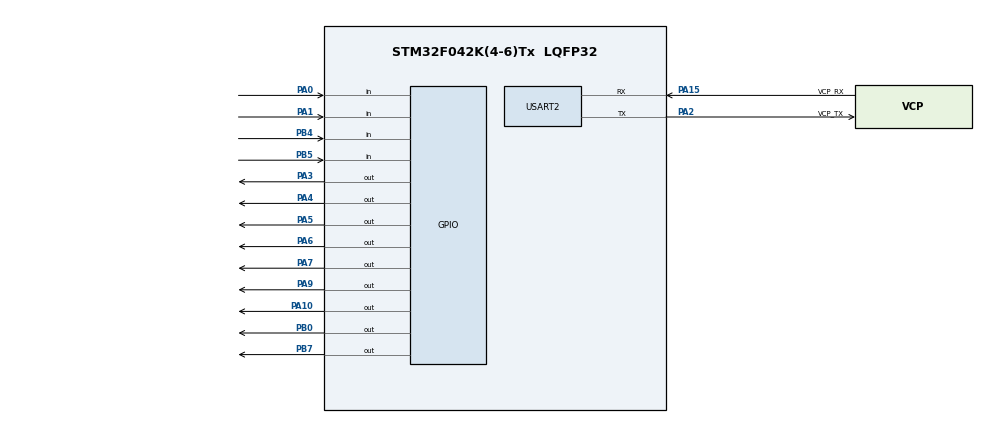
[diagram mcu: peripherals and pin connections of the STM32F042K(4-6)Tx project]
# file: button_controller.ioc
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Mcu.Family=STM32F0
Mcu.Name=STM32F042K(4-6)Tx
Mcu.Package=LQFP32
PA0.GPIO_PuPd=GPIO_PULLDOWN
PA0.Signal=GPIO_Input
PA1.Signal=GPIO_Input
PA10.Signal=GPIO_Output
PA13.GPIO_Label=SWDIO
PA13.Mode=Serial_Wire
PA13.Signal=SYS_SWDIO
PA14.GPIO_Label=SWCLK
PA14.Mode=Serial_Wire
PA14.Signal=SYS_SWCLK
PA15.GPIO_Label=VCP_RX
PA15.Mode=Asynchronous
PA15.Signal=USART2_RX
PA2.GPIO_Label=VCP_TX
PA2.Mode=Asynchronous
PA2.Signal=USART2_TX
PA3.Signal=GPIO_Output
PA4.Signal=GPIO_Output
PA5.Signal=GPIO_Output
PA6.Signal=GPIO_Output
PA7.Signal=GPIO_Output
PA9.Signal=GPIO_Output
PB0.Signal=GPIO_Output
PB4.Signal=GPIO_Input
PB5.Signal=GPIO_Input
PB7.Signal=GPIO_Output
PF0-OSC_IN.GPIO_Label=MCO
PF0-OSC_IN.Mode=HSE-External-Clock-Source
PF0-OSC_IN.Signal=RCC_OSC_IN
ProjectManager.HeapSize=0x200
ProjectManager.StackSize=0x400
ProjectManager.TargetToolchain=STM32CubeIDE
USART2.VirtualMode-Asynchronous=VM_ASYNC
board=NUCLEO-F042K6

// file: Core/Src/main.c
/* USER CODE BEGIN Header */
/**
  ******************************************************************************
  * @file           : main.c
  * @brief          : Main program body
  ******************************************************************************
  * @attention
  *
  * Copyright (c) 2025 STMicroelectronics.
  * All rights reserved.
  *
  * This software is licensed under terms that can be found in the LICENSE file
  * in the root directory of this software component.
  * If no LICENSE file comes with this software, it is provided AS-IS.
  *
  ******************************************************************************
  */
/* USER CODE END Header */
#include "main.h"

UART_HandleTypeDef huart2;

void SystemClock_Config(void);
static void MX_GPIO_Init(void);
static void MX_USART2_UART_Init(void);

int main(void)
{

  /* MCU Configuration--------------------------------------------------------*/

  /* Reset of all peripherals, Initializes the Flash interface and the Systick. */
  HAL_Init();

  /* Configure the system clock */
  SystemClock_Config();

  /* Initialize all configured peripherals */
  MX_GPIO_Init();
  MX_USART2_UART_Init();
  /* USER CODE BEGIN 2 */
  HAL_GPIO_WritePin(GPIOA, GPIO_PIN_3, GPIO_PIN_SET);
  /* USER CODE END 2 */

  /* Infinite loop */
  while (1)
  {

    /* USER CODE BEGIN 3 */
	GPIO_PinState pin = HAL_GPIO_ReadPin(GPIOA, GPIO_PIN_0);

	if (pin == GPIO_PIN_SET) {
	  HAL_UART_Transmit(&huart2, (uint8_t*)"1\r\n", 3, HAL_MAX_DELAY);
	} else {
	  HAL_UART_Transmit(&huart2, (uint8_t*)"0\r\n", 3, HAL_MAX_DELAY);
	}
  }
  /* USER CODE END 3 */
}

void SystemClock_Config(void)
{
  RCC_OscInitTypeDef RCC_OscInitStruct = {0};
  RCC_ClkInitTypeDef RCC_ClkInitStruct = {0};

  /** Initializes the RCC Oscillators according to the specified parameters
  * in the RCC_OscInitTypeDef structure.
  */
  RCC_OscInitStruct.OscillatorType = RCC_OSCILLATORTYPE_HSI;
  RCC_OscInitStruct.HSIState = RCC_HSI_ON;
  RCC_OscInitStruct.HSICalibrationValue = RCC_HSICALIBRATION_DEFAULT;
  RCC_OscInitStruct.PLL.PLLState = RCC_PLL_NONE;
  if (HAL_RCC_OscConfig(&RCC_OscInitStruct) != HAL_OK)
  {
    Error_Handler();
  }

  /** Initializes the CPU, AHB and APB buses clocks
  */
  RCC_ClkInitStruct.ClockType = RCC_CLOCKTYPE_HCLK|RCC_CLOCKTYPE_SYSCLK
                              |RCC_CLOCKTYPE_PCLK1;
  RCC_ClkInitStruct.SYSCLKSource = RCC_SYSCLKSOURCE_HSI;
  RCC_ClkInitStruct.AHBCLKDivider = RCC_SYSCLK_DIV1;
  RCC_ClkInitStruct.APB1CLKDivider = RCC_HCLK_DIV1;

  if (HAL_RCC_ClockConfig(&RCC_ClkInitStruct, FLASH_LATENCY_0) != HAL_OK)
  {
    Error_Handler();
  }
}

static void MX_USART2_UART_Init(void)
{

  huart2.Instance = USART2;
  huart2.Init.BaudRate = 38400;
  huart2.Init.WordLength = UART_WORDLENGTH_8B;
  huart2.Init.StopBits = UART_STOPBITS_1;
  huart2.Init.Parity = UART_PARITY_NONE;
  huart2.Init.Mode = UART_MODE_TX_RX;
  huart2.Init.HwFlowCtl = UART_HWCONTROL_NONE;
  huart2.Init.OverSampling = UART_OVERSAMPLING_16;
  huart2.Init.OneBitSampling = UART_ONE_BIT_SAMPLE_DISABLE;
  huart2.AdvancedInit.AdvFeatureInit = UART_ADVFEATURE_NO_INIT;
  if (HAL_UART_Init(&huart2) != HAL_OK)
  {
    Error_Handler();
  }

}

static void MX_GPIO_Init(void)
{
  GPIO_InitTypeDef GPIO_InitStruct = {0};

  /* GPIO Ports Clock Enable */
  __HAL_RCC_GPIOF_CLK_ENABLE();
  __HAL_RCC_GPIOA_CLK_ENABLE();
  __HAL_RCC_GPIOB_CLK_ENABLE();

  /*Configure GPIO pin Output Level */
  HAL_GPIO_WritePin(GPIOA, GPIO_PIN_3|GPIO_PIN_4|GPIO_PIN_5|GPIO_PIN_6
                          |GPIO_PIN_7|GPIO_PIN_9|GPIO_PIN_10, GPIO_PIN_RESET);

  /*Configure GPIO pin Output Level */
  HAL_GPIO_WritePin(GPIOB, GPIO_PIN_0|GPIO_PIN_7, GPIO_PIN_RESET);

  /*Configure GPIO pin : PA0 */
  GPIO_InitStruct.Pin = GPIO_PIN_0;
  GPIO_InitStruct.Mode = GPIO_MODE_INPUT;
  GPIO_InitStruct.Pull = GPIO_PULLDOWN;
  HAL_GPIO_Init(GPIOA, &GPIO_InitStruct);

  /*Configure GPIO pin : PA1 */
  GPIO_InitStruct.Pin = GPIO_PIN_1;
  GPIO_InitStruct.Mode = GPIO_MODE_INPUT;
  GPIO_InitStruct.Pull = GPIO_NOPULL;
  HAL_GPIO_Init(GPIOA, &GPIO_InitStruct);

  /*Configure GPIO pins : PA3 PA4 PA5 PA6
                           PA7 PA9 PA10 */
  GPIO_InitStruct.Pin = GPIO_PIN_3|GPIO_PIN_4|GPIO_PIN_5|GPIO_PIN_6
                          |GPIO_PIN_7|GPIO_PIN_9|GPIO_PIN_10;
  GPIO_InitStruct.Mode = GPIO_MODE_OUTPUT_PP;
  GPIO_InitStruct.Pull = GPIO_NOPULL;
  GPIO_InitStruct.Speed = GPIO_SPEED_FREQ_LOW;
  HAL_GPIO_Init(GPIOA, &GPIO_InitStruct);

  /*Configure GPIO pins : PB0 PB7 */
  GPIO_InitStruct.Pin = GPIO_PIN_0|GPIO_PIN_7;
  GPIO_InitStruct.Mode = GPIO_MODE_OUTPUT_PP;
  GPIO_InitStruct.Pull = GPIO_NOPULL;
  GPIO_InitStruct.Speed = GPIO_SPEED_FREQ_LOW;
  HAL_GPIO_Init(GPIOB, &GPIO_InitStruct);

  /*Configure GPIO pins : PB4 PB5 */
  GPIO_InitStruct.Pin = GPIO_PIN_4|GPIO_PIN_5;
  GPIO_InitStruct.Mode = GPIO_MODE_INPUT;
  GPIO_InitStruct.Pull = GPIO_NOPULL;
  HAL_GPIO_Init(GPIOB, &GPIO_InitStruct);

}

void Error_Handler(void)
{
  __disable_irq();
  while (1)
  {
  }
}
